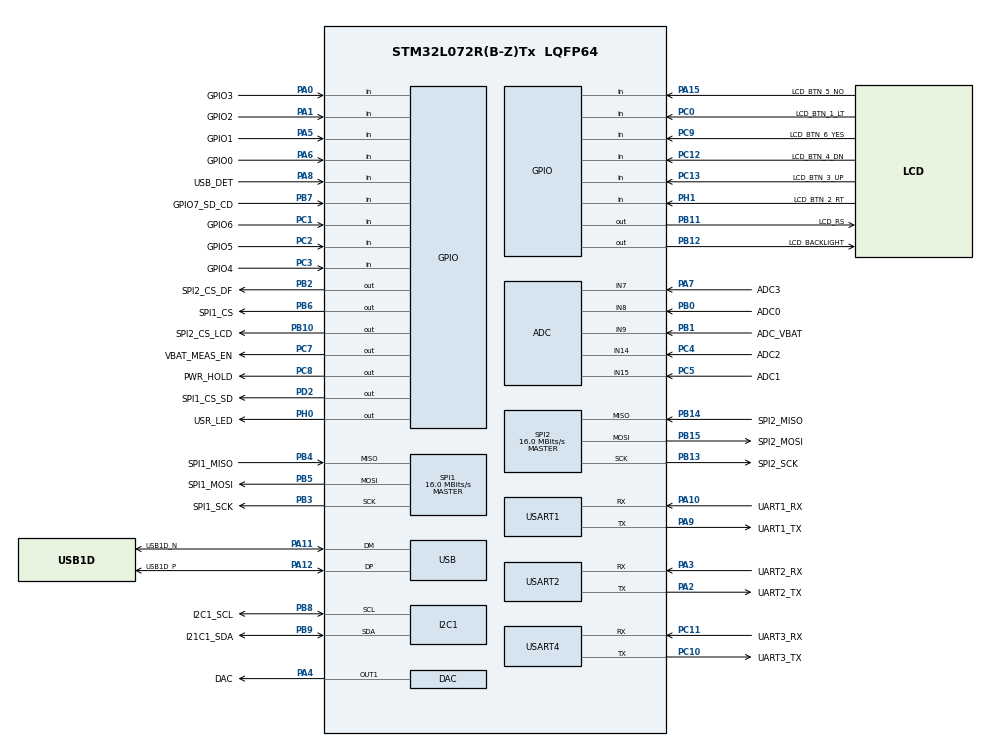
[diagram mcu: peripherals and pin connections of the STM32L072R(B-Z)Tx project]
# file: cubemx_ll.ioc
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I2C1.Timing=0x00707CBB
Mcu.Family=STM32L0
Mcu.Name=STM32L072R(B-Z)Tx
Mcu.Package=LQFP64
NVIC.TIM3_IRQn=true\:0\:0\:false\:false\:true\:true
NVIC.USB_IRQn=true\:0\:0\:false\:false\:true\:false
PA0.GPIO_Label=GPIO3
PA0.GPIO_PuPd=GPIO_PULLDOWN
PA0.Signal=GPIO_Input
PA1.GPIO_Label=GPIO2
PA1.GPIO_PuPd=GPIO_PULLDOWN
PA1.Signal=GPIO_Input
PA10.GPIO_Label=UART1_RX
PA10.GPIO_PuPd=GPIO_PULLUP
PA10.GPIO_Speed=GPIO_SPEED_FREQ_LOW
PA10.Mode=Asynchronous
PA10.Signal=USART1_RX
PA11.GPIO_Label=USB1D_N
PA11.Mode=Device
PA11.Signal=USB_DM
PA12.GPIO_Label=USB1D_P
PA12.Mode=Device
PA12.Signal=USB_DP
PA13.GPIO_Label=SWDIO
PA13.Mode=Serial_Wire
PA13.Signal=SYS_SWDIO
PA14.GPIO_Label=SWCLK
PA14.Mode=Serial_Wire
PA14.Signal=SYS_SWCLK
PA15.GPIO_Label=LCD_BTN_5_NO
PA15.GPIO_PuPd=GPIO_PULLUP
PA15.Signal=GPIO_Input
PA2.GPIO_Label=UART2_TX
PA2.GPIO_Speed=GPIO_SPEED_FREQ_LOW
PA2.Mode=Asynchronous
PA2.Signal=USART2_TX
PA3.GPIO_Label=UART2_RX
PA3.GPIO_PuPd=GPIO_PULLUP
PA3.GPIO_Speed=GPIO_SPEED_FREQ_LOW
PA3.Mode=Asynchronous
PA3.Signal=USART2_RX
PA4.GPIO_Label=DAC
PA4.Signal=COMP_DAC1_group
PA5.GPIO_Label=GPIO1
PA5.GPIO_PuPd=GPIO_PULLDOWN
PA5.Signal=GPIO_Input
PA6.GPIO_Label=GPIO0
PA6.GPIO_PuPd=GPIO_PULLDOWN
PA6.Signal=GPIO_Input
PA7.GPIO_Label=ADC3
PA7.Mode=IN7
PA7.Signal=ADC_IN7
PA8.GPIO_Label=USB_DET
PA8.Signal=GPIO_Input
PA9.GPIO_Label=UART1_TX
PA9.GPIO_Speed=GPIO_SPEED_FREQ_LOW
PA9.Mode=Asynchronous
PA9.Signal=USART1_TX
PB0.GPIO_Label=ADC0
PB0.Mode=IN8
PB0.Signal=ADC_IN8
PB1.GPIO_Label=ADC_VBAT
PB1.Mode=IN9
PB1.Signal=ADC_IN9
PB10.GPIO_Label=SPI2_CS_LCD
PB10.PinState=GPIO_PIN_SET
PB10.Signal=GPIO_Output
PB11.GPIO_Label=LCD_RS
PB11.Signal=GPIO_Output
PB12.GPIO_Label=LCD_BACKLIGHT
PB12.PinState=GPIO_PIN_SET
PB12.Signal=GPIO_Output
PB13.GPIO_Label=SPI2_SCK
PB13.GPIO_Speed=GPIO_SPEED_FREQ_LOW
PB13.Mode=Full_Duplex_Master
PB13.Signal=SPI2_SCK
PB14.GPIO_Label=SPI2_MISO
PB14.GPIO_Speed=GPIO_SPEED_FREQ_LOW
PB14.Mode=Full_Duplex_Master
PB14.Signal=SPI2_MISO
PB15.GPIO_Label=SPI2_MOSI
PB15.GPIO_Speed=GPIO_SPEED_FREQ_LOW
PB15.Mode=Full_Duplex_Master
PB15.Signal=SPI2_MOSI
PB2.GPIO_Label=SPI2_CS_DF
PB2.PinState=GPIO_PIN_SET
PB2.Signal=GPIO_Output
PB3.GPIO_Label=SPI1_SCK
PB3.GPIO_Speed=GPIO_SPEED_FREQ_LOW
PB3.Mode=Full_Duplex_Master
PB3.Signal=SPI1_SCK
PB4.GPIO_Label=SPI1_MISO
PB4.GPIO_PuPd=GPIO_PULLUP
PB4.GPIO_Speed=GPIO_SPEED_FREQ_LOW
PB4.Mode=Full_Duplex_Master
PB4.Signal=SPI1_MISO
PB5.GPIO_Label=SPI1_MOSI
PB5.GPIO_Speed=GPIO_SPEED_FREQ_LOW
PB5.Mode=Full_Duplex_Master
PB5.Signal=SPI1_MOSI
PB6.GPIO_Label=SPI1_CS
PB6.PinState=GPIO_PIN_SET
PB6.Signal=GPIO_Output
PB7.GPIO_Label=GPIO7_SD_CD
PB7.GPIO_PuPd=GPIO_PULLUP
PB7.Signal=GPIO_Input
PB8.GPIO_Label=I2C1_SCL
PB8.GPIO_PuPdOD=GPIO_NOPULL
PB8.GPIO_Speed=GPIO_SPEED_FREQ_LOW
PB8.Mode=I2C
PB8.Signal=I2C1_SCL
PB9.GPIO_Label=I21C1_SDA
PB9.GPIO_PuPdOD=GPIO_NOPULL
PB9.GPIO_Speed=GPIO_SPEED_FREQ_LOW
PB9.Mode=I2C
PB9.Signal=I2C1_SDA
PC0.GPIO_Label=LCD_BTN_1_LT
PC0.GPIO_PuPd=GPIO_PULLUP
PC0.Signal=GPIO_Input
PC1.GPIO_Label=GPIO6
PC1.GPIO_PuPd=GPIO_PULLDOWN
PC1.Signal=GPIO_Input
PC10.GPIO_Label=UART3_TX
PC10.GPIO_Speed=GPIO_SPEED_FREQ_LOW
PC10.Mode=Asynchronous
PC10.Signal=USART4_TX
PC11.GPIO_Label=UART3_RX
PC11.GPIO_PuPd=GPIO_PULLUP
PC11.GPIO_Speed=GPIO_SPEED_FREQ_LOW
PC11.Mode=Asynchronous
PC11.Signal=USART4_RX
PC12.GPIO_Label=LCD_BTN_4_DN
PC12.GPIO_PuPd=GPIO_PULLUP
PC12.Signal=GPIO_Input
PC13.GPIO_Label=LCD_BTN_3_UP
PC13.GPIO_PuPd=GPIO_PULLUP
PC13.Signal=GPIO_Input
PC14-OSC32_IN.GPIO_Label=OSC32_IN
PC14-OSC32_IN.Mode=LSE-External-Oscillator
PC14-OSC32_IN.Signal=RCC_OSC32_IN
PC15-OSC32_OUT.GPIO_Label=OSC32_OUT
PC15-OSC32_OUT.Mode=LSE-External-Oscillator
PC15-OSC32_OUT.Signal=RCC_OSC32_OUT
PC2.GPIO_Label=GPIO5
PC2.GPIO_PuPd=GPIO_PULLDOWN
PC2.Signal=GPIO_Input
PC3.GPIO_Label=GPIO4
PC3.GPIO_PuPd=GPIO_PULLDOWN
PC3.Signal=GPIO_Input
PC4.GPIO_Label=ADC2
PC4.Mode=IN14
PC4.Signal=ADC_IN14
PC5.GPIO_Label=ADC1
PC5.Mode=IN15
PC5.Signal=ADC_IN15
PC6.GPIO_Label=PWM_BUZZER
PC6.Signal=S_TIM22_CH1
PC7.GPIO_Label=VBAT_MEAS_EN
PC7.Signal=GPIO_Output
PC8.GPIO_Label=PWR_HOLD
PC8.PinState=GPIO_PIN_SET
PC8.Signal=GPIO_Output
PC9.GPIO_Label=LCD_BTN_6_YES
PC9.GPIO_PuPd=GPIO_PULLUP
PC9.Signal=GPIO_Input
PD2.GPIO_Label=SPI1_CS_SD
PD2.PinState=GPIO_PIN_SET
PD2.Signal=GPIO_Output
PH0-OSC_IN.GPIO_Label=USR_LED
PH0-OSC_IN.Signal=GPIO_Output
PH1-OSC_OUT.GPIO_Label=LCD_BTN_2_RT
PH1-OSC_OUT.GPIO_PuPd=GPIO_PULLUP
PH1-OSC_OUT.Signal=GPIO_Input
ProjectManager.HeapSize=0x200
ProjectManager.StackSize=0x400
ProjectManager.TargetToolchain=MDK-ARM V5
RCC.AHBFreq_Value=32000000
RCC.APB1Freq_Value=32000000
RCC.APB1TimFreq_Value=32000000
RCC.APB2Freq_Value=32000000
RCC.APB2TimFreq_Value=32000000
RCC.HCLKFreq_Value=32000000
RCC.HSE_VALUE=8000000
RCC.HSI16_VALUE=16000000
RCC.HSI48MClockSelection=RCC_USBCLKSOURCE_HSI48
RCC.HSI48_VALUE=48000000
RCC.HSI_VALUE=16000000
RCC.MSI_VALUE=2097000
RCC.PLLMUL=RCC_PLLMUL_4
RCC.RTCClockSelection=RCC_RTCCLKSOURCE_LSE
RCC.RTCClockSelectionVirtual=RCC_RTCCLKSOURCE_LSE
RCC.SYSCLKFreq_VALUE=32000000
RCC.SYSCLKSource=RCC_SYSCLKSOURCE_PLLCLK
RCC.VCOOutputFreq_Value=64000000
SH.COMP_DAC1_group.0=DAC_OUT1,DAC_OUT1
SH.S_TIM22_CH1.0=TIM22_CH1
SPI1.CalculateBaudRate=16.0 MBits/s
SPI1.Direction=SPI_DIRECTION_2LINES
SPI1.Mode=SPI_MODE_MASTER
SPI1.VirtualType=VM_MASTER
SPI2.CalculateBaudRate=16.0 MBits/s
SPI2.Direction=SPI_DIRECTION_2LINES
SPI2.Mode=SPI_MODE_MASTER
SPI2.VirtualType=VM_MASTER
USART1.VirtualMode-Asynchronous=VM_ASYNC
USART1.WordLength=WORDLENGTH_8B
USART2.VirtualMode-Asynchronous=VM_ASYNC
USART2.WordLength=WORDLENGTH_8B
USART4.VirtualMode-Asynchronous=VM_ASYNC
USART4.WordLength=WORDLENGTH_8B
USB_DEVICE.CLASS_NAME_FS=CDC
USB_DEVICE.MANUFACTURER_STRING=PICONOMIX
USB_DEVICE.PRODUCT_STRING_CDC_FS=Hero Board
USB_DEVICE.VirtualMode=Cdc
USB_DEVICE.VirtualModeFS=Cdc_FS
VP_FATFS_VS_Generic.Mode=User_defined
VP_RTC_VS_RTC_Activate.Mode=RTC_Enabled
VP_RTC_VS_RTC_Calendar.Mode=RTC_Calendar
VP_TIM3_VS_ClockSourceINT.Mode=Internal
VP_USB_DEVICE_VS_USB_DEVICE_CDC_FS.Mode=CDC_FS
board=cubemx_hal

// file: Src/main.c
/**
  ******************************************************************************
  * @file           : main.c
  * @brief          : Main program body
  ******************************************************************************
  * This notice applies to any and all portions of this file
  * that are not between comment pairs USER CODE BEGIN and
  * USER CODE END. Other portions of this file, whether
  * inserted by the user or by software development tools
  * are owned by their respective copyright owners.
  *
  * Copyright (c) 2018 STMicroelectronics International N.V.
  * All rights reserved.
  *
  * Redistribution and use in source and binary forms, with or without
  * modification, are permitted, provided that the following conditions are met:
  *
  * 1. Redistribution of source code must retain the above copyright notice,
  *    this list of conditions and the following disclaimer.
  * 2. Redistributions in binary form must reproduce the above copyright notice,
  *    this list of conditions and the following disclaimer in the documentation
  *    and/or other materials provided with the distribution.
  * 3. Neither the name of STMicroelectronics nor the names of other
  *    contributors to this software may be used to endorse or promote products
  *    derived from this software without specific written permission.
  * 4. This software, including modifications and/or derivative works of this
  *    software, must execute solely and exclusively on microcontroller or
  *    microprocessor devices manufactured by or for STMicroelectronics.
  * 5. Redistribution and use of this software other than as permitted under
  *    this license is void and will automatically terminate your rights under
  *    this license.
  *
  * THIS SOFTWARE IS PROVIDED BY STMICROELECTRONICS AND CONTRIBUTORS "AS IS"
  * AND ANY EXPRESS, IMPLIED OR STATUTORY WARRANTIES, INCLUDING, BUT NOT
  * LIMITED TO, THE IMPLIED WARRANTIES OF MERCHANTABILITY, FITNESS FOR A
  * PARTICULAR PURPOSE AND NON-INFRINGEMENT OF THIRD PARTY INTELLECTUAL PROPERTY
  * RIGHTS ARE DISCLAIMED TO THE FULLEST EXTENT PERMITTED BY LAW. IN NO EVENT
  * SHALL STMICROELECTRONICS OR CONTRIBUTORS BE LIABLE FOR ANY DIRECT, INDIRECT,
  * INCIDENTAL, SPECIAL, EXEMPLARY, OR CONSEQUENTIAL DAMAGES (INCLUDING, BUT NOT
  * LIMITED TO, PROCUREMENT OF SUBSTITUTE GOODS OR SERVICES; LOSS OF USE, DATA,
  * OR PROFITS; OR BUSINESS INTERRUPTION) HOWEVER CAUSED AND ON ANY THEORY OF
  * LIABILITY, WHETHER IN CONTRACT, STRICT LIABILITY, OR TORT (INCLUDING
  * NEGLIGENCE OR OTHERWISE) ARISING IN ANY WAY OUT OF THE USE OF THIS SOFTWARE,
  * EVEN IF ADVISED OF THE POSSIBILITY OF SUCH DAMAGE.
  *
  ******************************************************************************
  */
#include "main.h"
#include "stm32l0xx_hal.h"
#include "adc.h"
#include "dac.h"
#include "fatfs.h"
#include "i2c.h"
#include "rtc.h"
#include "spi.h"
#include "tim.h"
#include "usart.h"
#include "usb_device.h"
#include "gpio.h"

/* USER CODE BEGIN PV */
/* Private variables ---------------------------------------------------------*/

/* USER CODE END PV */

void SystemClock_Config(void);

/* USER CODE BEGIN PFP */
/* Private function prototypes -----------------------------------------------*/

/* USER CODE END PFP */

int main(void)
{

  /* MCU Configuration----------------------------------------------------------*/

  /* Reset of all peripherals, Initializes the Flash interface and the Systick. */
  HAL_Init();

  /* Configure the system clock */
  SystemClock_Config();

  /* Initialize all configured peripherals */
  MX_GPIO_Init();
  MX_ADC_Init();
  MX_DAC_Init();
  MX_I2C1_Init();
  MX_RTC_Init();
  MX_SPI1_Init();
  MX_SPI2_Init();
  MX_USART1_UART_Init();
  MX_USART2_UART_Init();
  MX_USART4_UART_Init();
  MX_USB_DEVICE_Init();
  MX_FATFS_Init();
  MX_TIM3_Init();

  /* Infinite loop */
  while (1)
  {

  /* USER CODE BEGIN 3 */
      // Button being pressed?
      if(!LL_GPIO_IsInputPinSet(LCD_BTN_6_YES_GPIO_Port, LCD_BTN_6_YES_Pin))
      {
          // Enable LED
          LL_GPIO_SetOutputPin(USR_LED_GPIO_Port, USR_LED_Pin);
          LL_GPIO_SetOutputPin(SPI1_CS_GPIO_Port, SPI1_CS_Pin);
      }
      else
      {
          // Disable LED
          LL_GPIO_ResetOutputPin(USR_LED_GPIO_Port, USR_LED_Pin);
      }

  }
  /* USER CODE END 3 */

}

void SystemClock_Config(void)
{

  LL_FLASH_SetLatency(LL_FLASH_LATENCY_1);

  if(LL_FLASH_GetLatency() != LL_FLASH_LATENCY_1)
  {
  Error_Handler();
  }
  LL_PWR_SetRegulVoltageScaling(LL_PWR_REGU_VOLTAGE_SCALE1);

  LL_RCC_HSI_Enable();

   /* Wait till HSI is ready */
  while(LL_RCC_HSI_IsReady() != 1)
  {

  }
  LL_RCC_HSI_SetCalibTrimming(16);

  LL_RCC_HSI48_Enable();

   /* Wait till HSI48 is ready */
  while(LL_RCC_HSI48_IsReady() != 1)
  {

  }
  LL_PWR_EnableBkUpAccess();

  LL_RCC_ForceBackupDomainReset();

  LL_RCC_ReleaseBackupDomainReset();

  LL_RCC_LSE_SetDriveCapability(LL_RCC_LSEDRIVE_LOW);

  LL_RCC_LSE_Enable();

   /* Wait till LSE is ready */
  while(LL_RCC_LSE_IsReady() != 1)
  {

  }
  LL_RCC_SetRTCClockSource(LL_RCC_RTC_CLKSOURCE_LSE);

  LL_RCC_EnableRTC();

  LL_RCC_PLL_ConfigDomain_SYS(LL_RCC_PLLSOURCE_HSI, LL_RCC_PLL_MUL_4, LL_RCC_PLL_DIV_2);

  LL_RCC_PLL_Enable();

   /* Wait till PLL is ready */
  while(LL_RCC_PLL_IsReady() != 1)
  {

  }
  LL_RCC_SetAHBPrescaler(LL_RCC_SYSCLK_DIV_1);

  LL_RCC_SetAPB1Prescaler(LL_RCC_APB1_DIV_1);

  LL_RCC_SetAPB2Prescaler(LL_RCC_APB2_DIV_1);

  LL_RCC_SetSysClkSource(LL_RCC_SYS_CLKSOURCE_PLL);

   /* Wait till System clock is ready */
  while(LL_RCC_GetSysClkSource() != LL_RCC_SYS_CLKSOURCE_STATUS_PLL)
  {

  }
  LL_Init1msTick(32000000);

  LL_SYSTICK_SetClkSource(LL_SYSTICK_CLKSOURCE_HCLK);

  LL_SetSystemCoreClock(32000000);

  LL_RCC_SetUSARTClockSource(LL_RCC_USART1_CLKSOURCE_PCLK2);

  LL_RCC_SetUSARTClockSource(LL_RCC_USART2_CLKSOURCE_PCLK1);

  LL_RCC_SetI2CClockSource(LL_RCC_I2C1_CLKSOURCE_PCLK1);

  LL_RCC_SetUSBClockSource(LL_RCC_USB_CLKSOURCE_HSI48);

  /* SysTick_IRQn interrupt configuration */
  NVIC_SetPriority(SysTick_IRQn, 0);
}

void _Error_Handler(char *file, int line)
{
  while(1)
  {
  }
}

/************************ (C) COPYRIGHT STMicroelectronics *****END OF FILE****/
